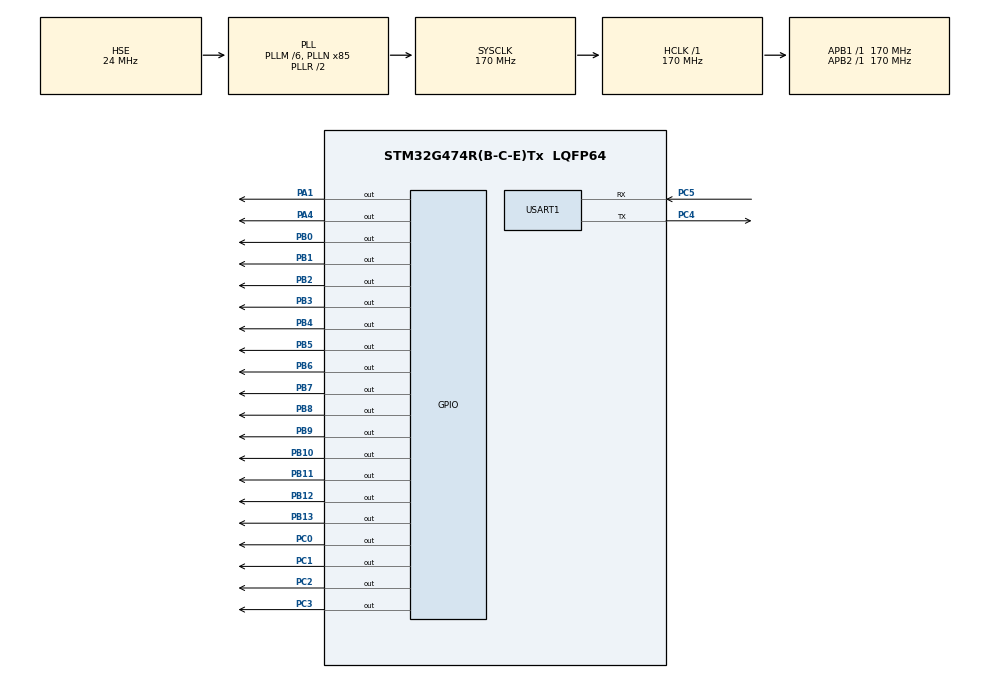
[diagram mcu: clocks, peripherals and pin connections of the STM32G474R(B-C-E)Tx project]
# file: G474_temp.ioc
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Mcu.Family=STM32G4
Mcu.Name=STM32G474R(B-C-E)Tx
Mcu.Package=LQFP64
NVIC.PriorityGroup=NVIC_PRIORITYGROUP_4
NVIC.USART1_IRQn=true\:0\:0\:false\:false\:true\:true\:true\:true
PA1.GPIO_Speed=GPIO_SPEED_FREQ_VERY_HIGH
PA1.PinState=GPIO_PIN_SET
PA1.Signal=GPIO_Output
PA13.Mode=Serial_Wire
PA13.Signal=SYS_JTMS-SWDIO
PA14.Mode=Serial_Wire
PA14.Signal=SYS_JTCK-SWCLK
PA4.GPIO_Speed=GPIO_SPEED_FREQ_VERY_HIGH
PA4.PinState=GPIO_PIN_SET
PA4.Signal=GPIO_Output
PB0.GPIO_Speed=GPIO_SPEED_FREQ_VERY_HIGH
PB0.PinState=GPIO_PIN_SET
PB0.Signal=GPIO_Output
PB1.GPIO_Speed=GPIO_SPEED_FREQ_VERY_HIGH
PB1.PinState=GPIO_PIN_SET
PB1.Signal=GPIO_Output
PB10.GPIO_Speed=GPIO_SPEED_FREQ_VERY_HIGH
PB10.PinState=GPIO_PIN_SET
PB10.Signal=GPIO_Output
PB11.PinState=GPIO_PIN_SET
PB11.Signal=GPIO_Output
PB12.GPIO_Speed=GPIO_SPEED_FREQ_VERY_HIGH
PB12.PinState=GPIO_PIN_SET
PB12.Signal=GPIO_Output
PB13.GPIO_Speed=GPIO_SPEED_FREQ_VERY_HIGH
PB13.PinState=GPIO_PIN_SET
PB13.Signal=GPIO_Output
PB2.GPIO_Speed=GPIO_SPEED_FREQ_VERY_HIGH
PB2.PinState=GPIO_PIN_SET
PB2.Signal=GPIO_Output
PB3.GPIO_Speed=GPIO_SPEED_FREQ_VERY_HIGH
PB3.PinState=GPIO_PIN_SET
PB3.Signal=GPIO_Output
PB4.PinState=GPIO_PIN_SET
PB4.Signal=GPIO_Output
PB5.GPIO_Speed=GPIO_SPEED_FREQ_VERY_HIGH
PB5.PinState=GPIO_PIN_SET
PB5.Signal=GPIO_Output
PB6.GPIO_FM6=__NULL
PB6.GPIO_Speed=GPIO_SPEED_FREQ_VERY_HIGH
PB6.PinState=GPIO_PIN_SET
PB6.Signal=GPIO_Output
PB7.GPIO_Speed=GPIO_SPEED_FREQ_VERY_HIGH
PB7.PinState=GPIO_PIN_SET
PB7.Signal=GPIO_Output
PB8-BOOT0.GPIO_Speed=GPIO_SPEED_FREQ_VERY_HIGH
PB8-BOOT0.PinState=GPIO_PIN_SET
PB8-BOOT0.Signal=GPIO_Output
PB9.PinState=GPIO_PIN_SET
PB9.Signal=GPIO_Output
PC0.GPIO_Speed=GPIO_SPEED_FREQ_VERY_HIGH
PC0.PinState=GPIO_PIN_SET
PC0.Signal=GPIO_Output
PC1.GPIO_Speed=GPIO_SPEED_FREQ_VERY_HIGH
PC1.PinState=GPIO_PIN_SET
PC1.Signal=GPIO_Output
PC14-OSC32_IN.Mode=LSE-External-Oscillator
PC14-OSC32_IN.Signal=RCC_OSC32_IN
PC15-OSC32_OUT.Mode=LSE-External-Oscillator
PC15-OSC32_OUT.Signal=RCC_OSC32_OUT
PC2.GPIO_Speed=GPIO_SPEED_FREQ_VERY_HIGH
PC2.PinState=GPIO_PIN_SET
PC2.Signal=GPIO_Output
PC3.GPIO_Speed=GPIO_SPEED_FREQ_VERY_HIGH
PC3.PinState=GPIO_PIN_SET
PC3.Signal=GPIO_Output
PC4.Mode=Asynchronous
PC4.Signal=USART1_TX
PC5.Mode=Asynchronous
PC5.Signal=USART1_RX
PF0-OSC_IN.Mode=HSE-External-Oscillator
PF0-OSC_IN.Signal=RCC_OSC_IN
PF1-OSC_OUT.Mode=HSE-External-Oscillator
PF1-OSC_OUT.Signal=RCC_OSC_OUT
ProjectManager.HeapSize=0x200
ProjectManager.StackSize=0x400
ProjectManager.TargetToolchain=MDK-ARM V5.32
RCC.ADC12Freq_Value=170000000
RCC.ADC345Freq_Value=170000000
RCC.AHBFreq_Value=170000000
RCC.APB1Freq_Value=170000000
RCC.APB1TimFreq_Value=170000000
RCC.APB2Freq_Value=170000000
RCC.APB2TimFreq_Value=170000000
RCC.CortexFreq_Value=170000000
RCC.EXTERNAL_CLOCK_VALUE=12288000
RCC.HCLKFreq_Value=170000000
RCC.HSE_VALUE=24000000
RCC.HSI48_VALUE=48000000
RCC.HSI_VALUE=16000000
RCC.PLLM=RCC_PLLM_DIV6
RCC.PLLN=85
RCC.PLLSourceVirtual=RCC_PLLSOURCE_HSE
RCC.RTCClockSelection=RCC_RTCCLKSOURCE_LSE
RCC.SYSCLKFreq_VALUE=170000000
RCC.SYSCLKSource=RCC_SYSCLKSOURCE_PLLCLK
RCC.USBFreq_Value=170000000
RCC.VCOOutputFreq_Value=340000000
USART1.VirtualMode-Asynchronous=VM_ASYNC
VP_SYS_VS_DBSignals.Mode=DisableDeadBatterySignals
board=NUCLEO-G474RE

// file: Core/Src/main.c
/* USER CODE BEGIN Header */
/**
  ******************************************************************************
  * @file           : main.c
  * @brief          : Main program body
  ******************************************************************************
  * @attention
  *
  * Copyright (c) 2023 STMicroelectronics.
  * All rights reserved.
  *
  * This software is licensed under terms that can be found in the LICENSE file
  * in the root directory of this software component.
  * If no LICENSE file comes with this software, it is provided AS-IS.
  *
  ******************************************************************************
  */
/* USER CODE END Header */
#include "main.h"
#include "usart.h"
#include "gpio.h"

/* USER CODE BEGIN Includes */
#include "delay.h"
#include "myusart1.h"
#include "OLED_I2C.h"
#include "AD9854_DR.h"
/* USER CODE END Includes */

void SystemClock_Config(void);

int main(void)
{

  /* MCU Configuration--------------------------------------------------------*/

  /* Reset of all peripherals, Initializes the Flash interface and the Systick. */
  HAL_Init();

  /* Configure the system clock */
  SystemClock_Config();

  /* Initialize all configured peripherals */
  MX_GPIO_Init();
  MX_USART1_UART_Init();
  /* USER CODE BEGIN 2 */
  delay_init(170);
  MyUSART1_Init(&huart1);
  //OLED_Init();
  //OLED_CLS();
  AD9854_Init();
  AD9854_SetSine(80000,4095);
  /* USER CODE END 2 */

  /* Infinite loop */
  while (1)
  {

  }
}

void SystemClock_Config(void)
{
  RCC_OscInitTypeDef RCC_OscInitStruct = {0};
  RCC_ClkInitTypeDef RCC_ClkInitStruct = {0};

  /** Configure the main internal regulator output voltage
  */
  HAL_PWREx_ControlVoltageScaling(PWR_REGULATOR_VOLTAGE_SCALE1_BOOST);

  /** Initializes the RCC Oscillators according to the specified parameters
  * in the RCC_OscInitTypeDef structure.
  */
  RCC_OscInitStruct.OscillatorType = RCC_OSCILLATORTYPE_HSE;
  RCC_OscInitStruct.HSEState = RCC_HSE_ON;
  RCC_OscInitStruct.PLL.PLLState = RCC_PLL_ON;
  RCC_OscInitStruct.PLL.PLLSource = RCC_PLLSOURCE_HSE;
  RCC_OscInitStruct.PLL.PLLM = RCC_PLLM_DIV6;
  RCC_OscInitStruct.PLL.PLLN = 85;
  RCC_OscInitStruct.PLL.PLLP = RCC_PLLP_DIV2;
  RCC_OscInitStruct.PLL.PLLQ = RCC_PLLQ_DIV2;
  RCC_OscInitStruct.PLL.PLLR = RCC_PLLR_DIV2;
  if (HAL_RCC_OscConfig(&RCC_OscInitStruct) != HAL_OK)
  {
    Error_Handler();
  }

  /** Initializes the CPU, AHB and APB buses clocks
  */
  RCC_ClkInitStruct.ClockType = RCC_CLOCKTYPE_HCLK|RCC_CLOCKTYPE_SYSCLK
                              |RCC_CLOCKTYPE_PCLK1|RCC_CLOCKTYPE_PCLK2;
  RCC_ClkInitStruct.SYSCLKSource = RCC_SYSCLKSOURCE_PLLCLK;
  RCC_ClkInitStruct.AHBCLKDivider = RCC_SYSCLK_DIV1;
  RCC_ClkInitStruct.APB1CLKDivider = RCC_HCLK_DIV1;
  RCC_ClkInitStruct.APB2CLKDivider = RCC_HCLK_DIV1;

  if (HAL_RCC_ClockConfig(&RCC_ClkInitStruct, FLASH_LATENCY_4) != HAL_OK)
  {
    Error_Handler();
  }
}

void Error_Handler(void)
{
  __disable_irq();
  while (1)
  {
  }
}
